# GT32U2086 register map
Vendor: FPTTelecom
Registers are 32-bit, read-write, reset 0x0 unless marked. A register's access mark holds for its fields unless they carry their own. Offsets are from the block's base; [hi:lo] are bit positions; lines under a group give offsets from that group; {n}, {i} and the like mark numbered series.

## CRM — CRM - GT32U2086 v8 clock and reset module. Offsets follow CSR_CRM_gt32u2086_v2_ea.xlsx as implemented by the VP.
Base 0x50010000
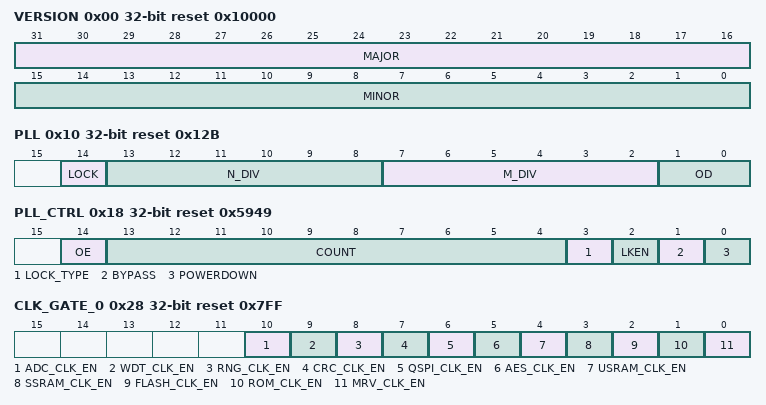
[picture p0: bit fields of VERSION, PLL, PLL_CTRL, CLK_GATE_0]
0x00 VERSION ro reset 0x10000 — CRM version
  [31:16] MAJOR — Major version
  [15:0] MINOR — Minor version
0x10 PLL reset 0x12B — PLL divider and lock
  [14] LOCK — Hardware lock indication
  [13:8] N_DIV — N divider
  [7:2] M_DIV — M divider
  [1:0] OD — Output divider
0x18 PLL_CTRL reset 0x5949 — PLL control
  [14] OE — PLL output enable
  [13:4] COUNT — Lock counter
  [3] LOCK_TYPE
  [2] LKEN — Enable lock detector
  [1] BYPASS — Bypass PLL
  [0] POWERDOWN — Power down PLL
0x1C CLK_0 — Clock selector 0
  [0] SEL — Clock selection
0x20 CLK_1 — Clock selector 1
  [0] SEL — Clock selection
0x24 CLK — Clock divider
  [9:0] DIV — Clock divisor
0x28 CLK_GATE_0 reset 0x7FF — Clock gate group 0
  [10] ADC_CLK_EN — Enable ADC clock
  [9] WDT_CLK_EN — Enable watchdog clock
  [8] RNG_CLK_EN — Enable random-number-generator clock
  [7] CRC_CLK_EN — Enable CRC clock
  [6] QSPI_CLK_EN — Enable QSPI clock
  [5] AES_CLK_EN — Enable AES clock
  [4] USRAM_CLK_EN — Enable user SRAM clock
  [3] SSRAM_CLK_EN — Enable system SRAM clock
  [2] FLASH_CLK_EN — Enable internal Flash clock
  [1] ROM_CLK_EN — Enable boot ROM clock
  [0] MRV_CLK_EN — Enable MRV clock
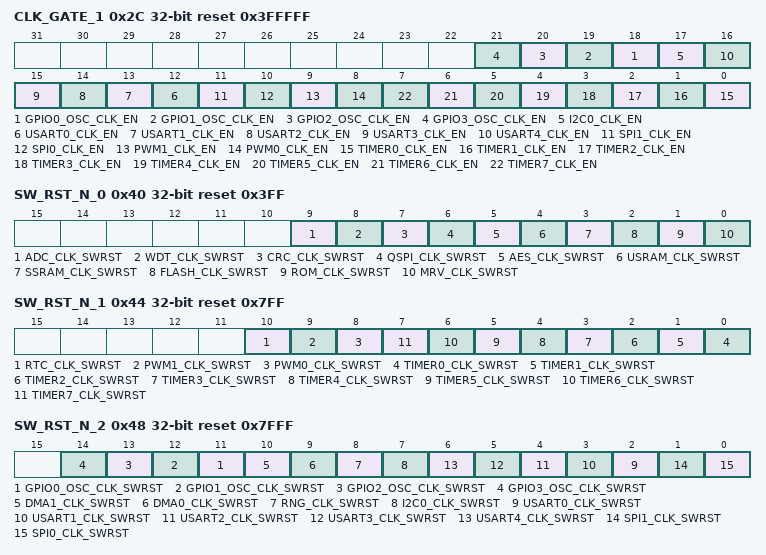
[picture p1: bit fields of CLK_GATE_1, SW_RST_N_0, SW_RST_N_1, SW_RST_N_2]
0x2C CLK_GATE_1 reset 0x3FFFFF — Clock gate group 1
  [n+18] GPIO{n}_OSC_CLK_EN (n=0..3) — Enable GPIO clock domain {n}
  [17] I2C0_CLK_EN — Enable I2C 0 clock
  [n+12] USART{n}_CLK_EN (n=0..4) — Enable UART {n} clock
  [11] SPI1_CLK_EN — Enable SPI 1 clock
  [10] SPI0_CLK_EN — Enable SPI 0 clock
  [9] PWM1_CLK_EN — Enable PWM 1 clock
  [8] PWM0_CLK_EN — Enable PWM 0 clock
  [n] TIMER{n}_CLK_EN (n=0..7) — Enable timer {n} clock
0x30 FCLK_SW — Active-low domain reset control
  [0] RST_N — Release domain reset
0x34 ACLK_SW reset 0x1 — Active-low domain reset control
  [0] RST_N — Release domain reset
0x38 PCLK_0_SW reset 0x1 — Active-low domain reset control
  [0] RST_N — Release domain reset
0x3C PCLK_1_SW reset 0x1 — Active-low domain reset control
  [0] RST_N — Release domain reset
0x40 SW_RST_N_0 reset 0x3FF — Peripheral reset group 0
  [9] ADC_CLK_SWRST — Release ADC reset
  [8] WDT_CLK_SWRST — Release watchdog reset
  [7] CRC_CLK_SWRST — Release CRC reset
  [6] QSPI_CLK_SWRST — Release QSPI reset
  [5] AES_CLK_SWRST — Release AES reset
  [4] USRAM_CLK_SWRST — Release user SRAM reset
  [3] SSRAM_CLK_SWRST — Release system SRAM reset
  [2] FLASH_CLK_SWRST — Release internal Flash reset
  [1] ROM_CLK_SWRST — Release boot ROM reset
  [0] MRV_CLK_SWRST — Release MRV reset
0x44 SW_RST_N_1 reset 0x7FF — Peripheral reset group 1
  [10] RTC_CLK_SWRST — Release RTC reset
  [9] PWM1_CLK_SWRST — Release PWM 1 reset
  [8] PWM0_CLK_SWRST — Release PWM 0 reset
  [n] TIMER{n}_CLK_SWRST (n=0..7) — Release timer {n} reset
0x48 SW_RST_N_2 reset 0x7FFF — Peripheral reset group 2
  [n+11] GPIO{n}_OSC_CLK_SWRST (n=0..3) — Release GPIO reset domain {n}
  [10] DMA1_CLK_SWRST — Release DMA 1 reset
  [9] DMA0_CLK_SWRST — Release DMA 0 reset
  [8] RNG_CLK_SWRST — Release random-number-generator reset
  [7] I2C0_CLK_SWRST — Release I2C 0 reset
  [n+2] USART{n}_CLK_SWRST (n=0..4) — Release UART {n} reset
  [1] SPI1_CLK_SWRST — Release SPI 1 reset
  [0] SPI0_CLK_SWRST — Release SPI 0 reset
0x4C CPU_DEBUG — CPU debug reset control
  [0] RST_N — Release CPU debug reset
0x50 SYSTEM_CLK_SW — System clock reset control
  [0] RST_N — Release system clock reset
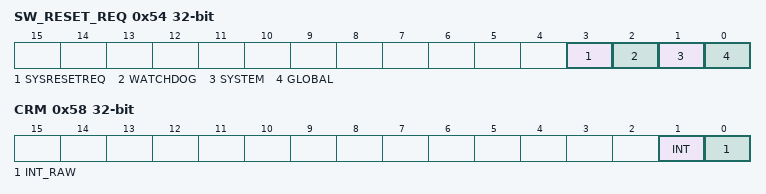
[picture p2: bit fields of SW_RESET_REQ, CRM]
0x54 SW_RESET_REQ ro — Latched reset requests
  [3] SYSRESETREQ — CPU SYSRESETREQ
  [2] WATCHDOG — Watchdog reset request
  [1] SYSTEM — System reset request
  [0] GLOBAL — Global reset request
0x58 CRM — CRM interrupt register
  [1] INT — Interrupt output
  [0] INT_RAW — Raw interrupt, W1C
